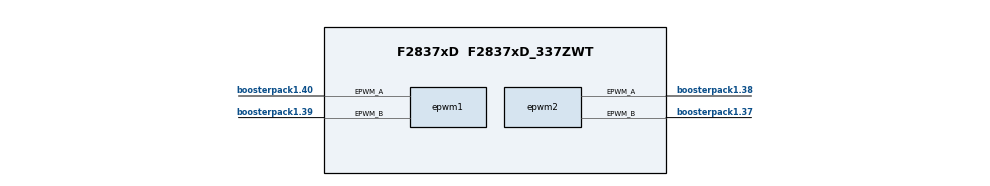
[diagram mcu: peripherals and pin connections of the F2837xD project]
/**
 * @cliArgs --board "/boards/LAUNCHXL_F28379D" --device "F2837xD" --part "F2837xD_337ZWT" --package "F2837xD_337ZWT" --context "CPU1" --product "C2000WARE@26.00.00.00"
 * @versions {"tool":"1.27.0+4565"}
 */

/**
 * Import the modules used in this configuration.
 */
const adc    = scripting.addModule("/driverlib/adc.js", {}, false);
const adc1   = adc.addInstance();
const adc2   = adc.addInstance();
const epwm   = scripting.addModule("/driverlib/epwm.js", {}, false);
const epwm1  = epwm.addInstance();
const epwm2  = epwm.addInstance();
const memcfg = scripting.addModule("/driverlib/memcfg.js");

/**
 * Write custom configuration values to the imported modules.
 */
adc1.$name              = "myADC0";
adc1.adcClockPrescaler  = "ADC_CLK_DIV_4_0";
adc1.enabledSOCs        = ["ADC_SOC_NUMBER0"];
adc1.soc0Channel        = "ADC_CH_ADCIN2";
adc1.soc0Trigger        = "ADC_TRIGGER_EPWM1_SOCA";
adc1.soc0SampleWindow   = 15;
adc1.interruptPulseMode = "ADC_PULSE_END_OF_CONV";
adc1.enabledInts        = ["ADC_INT_NUMBER1"];
adc1.useInterrupts      = false;

adc2.$name                   = "myADC1";
adc2.adcBase                 = "ADCB_BASE";
adc2.adcClockPrescaler       = "ADC_CLK_DIV_4_0";
adc2.enabledSOCs             = ["ADC_SOC_NUMBER0"];
adc2.soc0Channel             = "ADC_CH_ADCIN2";
adc2.soc0Trigger             = "ADC_TRIGGER_EPWM1_SOCA";
adc2.soc0SampleWindow        = 15;
adc2.interruptPulseMode      = "ADC_PULSE_END_OF_CONV";
adc2.enabledInts             = ["ADC_INT_NUMBER1"];
adc2.enableInterrupt1        = true;
adc2.registerInterrupts      = ["1"];
adc2.adcInt1.enableInterrupt = true;

epwm1.$name                                                      = "myEPWM0";
epwm1.$hardware                                                  = system.deviceData.board.components.BP_SITE_1.subComponents.PWM_LOC1;
epwm1.epwmTimebase_hsClockDiv                                    = "EPWM_HSCLOCK_DIVIDER_1";
epwm1.epwmTimebase_period                                        = 2500;
epwm1.epwmTimebase_counterMode                                   = "EPWM_COUNTER_MODE_UP_DOWN";
epwm1.epwmCounterCompare_cmpA                                    = 1250;
epwm1.epwmActionQualifier_EPWM_AQ_OUTPUT_A_ON_TIMEBASE_DOWN_CMPA = "EPWM_AQ_OUTPUT_HIGH";
epwm1.epwmActionQualifier_EPWM_AQ_OUTPUT_A_ON_TIMEBASE_UP_CMPA   = "EPWM_AQ_OUTPUT_LOW";
epwm1.epwmEventTrigger_EPWM_SOC_A_triggerEnable                  = true;
epwm1.epwmEventTrigger_EPWM_SOC_A_triggerSource                  = "EPWM_SOC_TBCTR_ZERO";
epwm1.epwmEventTrigger_EPWM_SOC_A_triggerEventPrescalar          = "1";
epwm1.epwmDeadband_polarityFED                                   = "EPWM_DB_POLARITY_ACTIVE_LOW";
epwm1.epwmDeadband_enableRED                                     = true;
epwm1.epwmDeadband_enableFED                                     = true;
epwm1.epwmDeadband_delayRED                                      = 10;
epwm1.epwmDeadband_delayFED                                      = 10;
epwm1.epwmTimebase_syncOutPulseMode                              = "EPWM_SYNC_OUT_PULSE_ON_COUNTER_ZERO";
epwm1.epwm.$assign                                               = "EPWM1";
epwm1.epwm.epwm_aPin.$assign                                     = "boosterpack1.40";
epwm1.epwm.epwm_bPin.$assign                                     = "boosterpack1.39";

epwm2.$name                                                      = "myEPWM1";
epwm2.$hardware                                                  = system.deviceData.board.components.BP_SITE_1.subComponents.PWM_LOC2;
epwm2.epwmTimebase_hsClockDiv                                    = "EPWM_HSCLOCK_DIVIDER_1";
epwm2.epwmTimebase_period                                        = 2500;
epwm2.epwmTimebase_counterMode                                   = "EPWM_COUNTER_MODE_UP_DOWN";
epwm2.epwmTimebase_phaseEnable                                   = true;
epwm2.epwmTimebase_counterModeAfterSync                          = "EPWM_COUNT_MODE_UP_AFTER_SYNC";
epwm2.epwmActionQualifier_EPWM_AQ_OUTPUT_A_ON_TIMEBASE_UP_CMPA   = "EPWM_AQ_OUTPUT_LOW";
epwm2.epwmActionQualifier_EPWM_AQ_OUTPUT_A_ON_TIMEBASE_DOWN_CMPA = "EPWM_AQ_OUTPUT_HIGH";
epwm2.epwmDeadband_polarityFED                                   = "EPWM_DB_POLARITY_ACTIVE_LOW";
epwm2.epwmDeadband_enableFED                                     = true;
epwm2.epwmDeadband_delayRED                                      = 10;
epwm2.epwmDeadband_enableRED                                     = true;
epwm2.epwmDeadband_delayFED                                      = 10;
epwm2.epwm.$assign                                               = "EPWM2";
epwm2.epwm.epwm_aPin.$assign                                     = "boosterpack1.38";
epwm2.epwm.epwm_bPin.$assign                                     = "boosterpack1.37";

memcfg.init_MEMCFG_SECT_MSGCPUTOCLA1 = true;
memcfg.init_MEMCFG_SECT_MSGCLA1TOCPU = true;
memcfg.config_MEMCFG_SECT_LS1        = "CLA_data";
memcfg.config_MEMCFG_SECT_LS4        = "CLA_prog";
memcfg.config_MEMCFG_SECT_LS5        = "CLA_prog";
